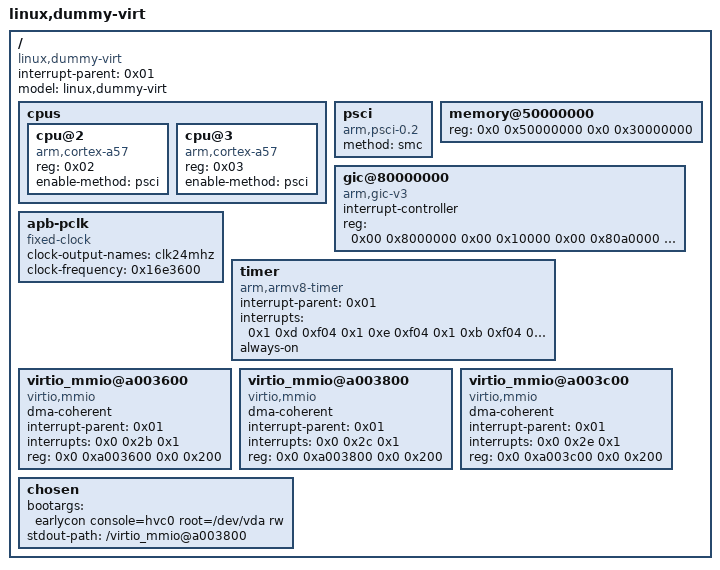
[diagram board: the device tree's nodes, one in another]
/dts-v1/;

/ {
	#size-cells = <0x2>;
	#address-cells = <0x2>;
	interrupt-parent = <0x01>;
	model = "linux,dummy-virt";
	compatible = "linux,dummy-virt";

	cpus {
		#size-cells = <0x00>;
		#address-cells = <0x01>;

		cpu@2 {
			reg = <0x02>;
			enable-method = "psci";
			compatible = "arm,cortex-a57";
			device_type = "cpu";
		};

		cpu@3 {
			reg = <0x03>;
			enable-method = "psci";
			compatible = "arm,cortex-a57";
			device_type = "cpu";
		};

	};

	psci {
		compatible = "arm,psci-0.2";
		method = "smc";
	};
	
	memory@50000000 {
		device_type = "memory";
		reg = <0x0 0x50000000 0x0 0x30000000>;
	};

	gic@80000000 {
		compatible = "arm,gic-v3";
		#interrupt-cells = <0x03>;
		interrupt-controller;
		reg = <0x00 0x8000000 0x00 0x10000 0x00 0x80a0000 0x00 0xf60000>;
		phandle = <0x01>;
	};

	apb-pclk {
		phandle = <0x8000>;
		clock-output-names = "clk24mhz";
		clock-frequency = <0x16e3600>;
		#clock-cells = <0x00>;
		compatible = "fixed-clock";
	};

	// pl011@9000000 {
	// 	clock-names = "uartclk\0apb_pclk";
	// 	clocks = <0x8000 0x8000>;
	// 	interrupt-parent = <0x01>;
	// 	interrupts = <0x00 0x01 0x04>;
	// 	reg = <0x00 0x9000000 0x00 0x1000>;
	// 	compatible = "arm,pl011\0arm,primecell";
	// };

	timer {
		interrupt-parent = <0x01>;
		interrupts = <0x1 0xd 0xf04 0x1 0xe 0xf04 0x1 0xb 0xf04 0x1 0xa 0xf04>;
		always-on;
		compatible = "arm,armv8-timer", "arm,armv7-timer";
	};

	// virtio_mmio@a003000 {
	// 	dma-coherent;
	// 	interrupts = <0x0 0x28 0x1>;
	// 	reg = <0x0 0xa003000 0x0 0x200>;
	// 	compatible = "virtio,mmio";
	// };

	// virtio_mmio@a003200 {
	// 	dma-coherent;
	// 	interrupts = <0x0 0x29 0x1>;
	// 	reg = <0x0 0xa003200 0x0 0x200>;
	// 	compatible = "virtio,mmio";
	// };

	// virtio_mmio@a003400 {
	// 	dma-coherent;
	// 	interrupts = <0x0 0x2a 0x1>;
	// 	reg = <0x0 0xa003400 0x0 0x200>;
	// 	compatible = "virtio,mmio";
	// };
	// virtio-net
	virtio_mmio@a003600 {
		dma-coherent;
		interrupt-parent = <0x01>;
		interrupts = <0x0 0x2b 0x1>;
		reg = <0x0 0xa003600 0x0 0x200>;
		compatible = "virtio,mmio";
	};

	// virtio serial
	virtio_mmio@a003800 {
		dma-coherent;
		interrupt-parent = <0x01>;
		interrupts = <0x0 0x2c 0x1>;
		reg = <0x0 0xa003800 0x0 0x200>;
		compatible = "virtio,mmio";
	};

	// virtio net
	// virtio_mmio@a003a00 {
	// 	dma-coherent;
	// 	interrupts = <0x0 0x2d 0x1>;
	// 	reg = <0x0 0xa003a00 0x0 0x200>;
	// 	compatible = "virtio,mmio";
	// };

	// virtio-blk
	virtio_mmio@a003c00 {
		dma-coherent;
		interrupt-parent = <0x01>;
		interrupts = <0x0 0x2e 0x1>;
		reg = <0x0 0xa003c00 0x0 0x200>;
		compatible = "virtio,mmio";
	};

	// virtio disk-first
	// virtio_mmio@a003e00 {
	// 	dma-coherent;
	// 	interrupts = <0x0 0x2f 0x1>;
	// 	reg = <0x0 0xa003e00 0x0 0x200>;
	// 	compatible = "virtio,mmio";
	// };

	chosen {
		bootargs = "earlycon console=hvc0 root=/dev/vda rw";
        // bootargs = "root=/dev/vda mem=768M";
		stdout-path = "/virtio_mmio@a003800";
	};

};
